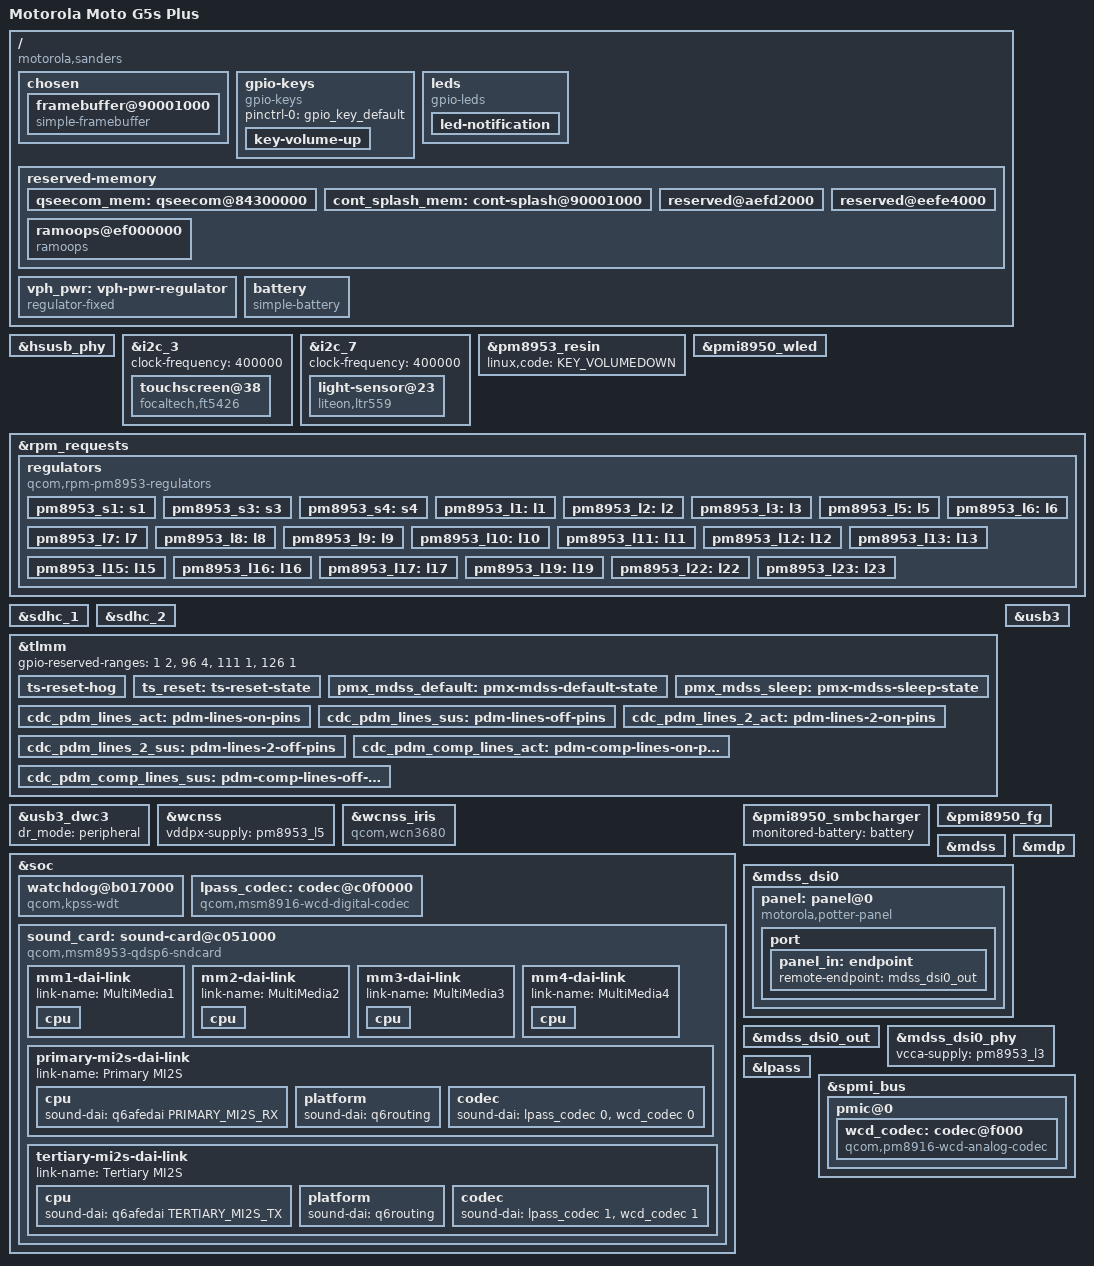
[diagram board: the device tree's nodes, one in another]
// SPDX-License-Identifier: BSD-3-Clause
/*
 * Motorola Moto G5s Plus (sanders) — proof-of-life DTS.
 * Derivado de msm8953-motorola-potter.dts (Moto G5 Plus). Hardware base
 * idêntico (msm8953 + pm8953 + pmi8950, display 1080x1920, MMC, USB, touch
 * Synaptics RMI4). Painel pode diferir (Tianma NT35596 ou DJN ILI7807D no
 * sanders); por enquanto reaproveitamos só o cont_splash_mem do bootloader.
 */
/dts-v1/;

#include "msm8953.dtsi"
#include "pm8953.dtsi"
#include "pmi8950.dtsi"

/delete-node/ &cont_splash_mem;
/delete-node/ &qseecom_mem;

/ {
	model = "Motorola Moto G5s Plus";
	compatible = "motorola,sanders", "qcom,msm8953";
	chassis-type = "handset";
	qcom,msm-id = <293 0>;
	/* Cobre todas as 6 variantes do sanders no fork lk2nd:
	 * p1, p2, p3-1, p3-2, p4-1, p4-2. lk2nd casa contra
	 * lk2nd_dt_override e seleciona automaticamente. */
	qcom,board-id = <0x4B 0x8100>,
			<0x4B 0x8200>,
			<0x4B 0x8300>,
			<0x4B 0x83B0>,
			<0x4B 0x8400>,
			<0x4C 0x8400>;

	chosen {
		#address-cells = <2>;
		#size-cells = <2>;
		ranges;

		framebuffer@90001000 {
			compatible = "simple-framebuffer";
			/* Era (2220 * 1920 * 3) = 12.787.200 bytes — quase o
			 * dobro do que cont_splash_mem reserva (1080*1920*3 =
			 * 6.220.800, no-map). simplefb.c faz
			 * ioremap_wc(smem_start, resource_size(mem)) usando o
			 * tamanho cheio do reg, nao width*height*stride — os
			 * ~6.5MB extras mapeados write-combining cairiam em
			 * RAM normal nao reservada, dual-mapped com atributos
			 * de cache incompativeis (risco real de corrupcao).
			 * 1080, nao 2220 — bate com stride (1080*3=3240) *
			 * height (1920) e com o cont_splash_mem real. */
			reg = <0 0x90001000 0 (1080 * 1920 * 3)>;

			width = <1080>;
			height = <1920>;
			stride = <(1080 * 3)>;
			format = "r8g8b8";

			power-domains = <&gcc MDSS_GDSC>;

			clocks = <&gcc GCC_MDSS_AHB_CLK>,
				 <&gcc GCC_MDSS_AXI_CLK>,
				 <&gcc GCC_MDSS_VSYNC_CLK>,
				 <&gcc GCC_MDSS_MDP_CLK>,
				 <&gcc GCC_MDSS_BYTE0_CLK>,
				 <&gcc GCC_MDSS_PCLK0_CLK>,
				 <&gcc GCC_MDSS_ESC0_CLK>;
		};
	};

	gpio-keys {
		compatible = "gpio-keys";

		pinctrl-names = "default";
		pinctrl-0 = <&gpio_key_default>;

		key-volume-up {
			label = "Volume Up";
			gpios = <&tlmm 85 GPIO_ACTIVE_LOW>;
			linux,code = <KEY_VOLUMEUP>;
		};
	};

	/*
	 * LED de notificacao frontal — branco unico, ligado no MPP2 do
	 * pmi8950 como current-sink. Downstream Moto (qpnp-leds) usava modo
	 * "manual" com source-sel=1 e current=5mA. No mainline atual nao ha
	 * driver MPP-as-current-sink; usamos leds-gpio (on/off apenas).
	 * Brilho/PWM via pmi8950_pwm fica como upgrade futuro.
	 */
	leds {
		compatible = "gpio-leds";

		led-notification {
			label = "white:notification";
			gpios = <&pmi8950_mpps 1 GPIO_ACTIVE_HIGH>;
			default-state = "off";
		};
	};

	reserved-memory {
		qseecom_mem: qseecom@84300000 {
			reg = <0x0 0x84300000 0x0 0x2000000>;
			no-map;
		};

		cont_splash_mem: cont-splash@90001000 {
			reg = <0x0 0x90001000 0x0 (1080 * 1920 * 3)>;
			no-map;
		};

		reserved@aefd2000 {
			reg = <0x0 0xaefd2000 0x0 0x2e000>;
			no-map;
		};

		reserved@eefe4000 {
			reg = <0x0 0xeefe4000 0x0 0x1c000>;
			no-map;
		};

		ramoops@ef000000 {
			compatible = "ramoops";
			reg = <0x0 0xef000000 0x0 0x80000>;
			console-size = <0x40000>;
			ftrace-size = <0>;
			record-size = <0x3f800>;
			pmsg-size = <0x800>;
		};
	};

	vph_pwr: vph-pwr-regulator {
		compatible = "regulator-fixed";
		regulator-name = "vph_pwr";
		regulator-always-on;
		regulator-boot-on;
	};

	/*
	 * Valores extraidos do DTB de fabrica real (decompilado de
	 * chroot_rootfs_motorola-potter/boot/msm8953-motorola-potter.dtb,
	 * mesma bateria do sanders/potter): charge-full-design 0x2e5b30 =
	 * 3038000 uAh, voltage-min 0x33e140 = 3400000 uV, voltage-max
	 * 0x432380 = 4400000 uV, constant-charge-current-max 0xf4240 =
	 * 1000000 uA. So a descricao da bateria; nao ha driver mainline
	 * pra charger/fuel-gauge deste PMIC ainda (ver &pmi8950_smbcharger
	 * e &pmi8950_fg abaixo) — os numeros ficam prontos pro dia que
	 * existir driver.
	 */
	battery: battery {
		compatible = "simple-battery";
		charge-full-design-microamp-hours = <3038000>;
		voltage-min-design-microvolt = <3400000>;
		voltage-max-design-microvolt = <4400000>;
		constant-charge-current-max-microamp = <1000000>;
	};
};



&hsusb_phy {
	vdd-supply = <&pm8953_l3>;
	vdda-pll-supply = <&pm8953_l7>;
	vdda-phy-dpdm-supply = <&pm8953_l13>;

	status = "okay";
};

&i2c_3 {
	status = "okay";
	clock-frequency = <400000>;	/* stock Android usa 400kHz no FT5436 */

	/* Forca PIO (sem DMA) — o controller mainline pode estar com
	 * bug DMA em transactions especificas do FT5436. */
	/delete-property/ dmas;
	/delete-property/ dma-names;

	/* Moto G5s Plus stock Android usa Focaltech FT5436 @ 0x38 com
	 * VDD em pm8953_l10 (2.85V, always-on) e VCC_I2C em pm8953_l5
	 * (1.8V). Reset GPIO 64, IRQ GPIO 65. (Nao Synaptics RMI4 como
	 * o irmao potter.) */
	touchscreen@38 {
		reg = <0x38>;
		compatible = "focaltech,ft5426";

		interrupt-parent = <&tlmm>;
		interrupts = <65 IRQ_TYPE_EDGE_FALLING>;

		/* Reset GPIO controlado via gpio-hog (sempre HIGH) — o pulse
		 * curto do driver (~5ms) estava deixando o chip num estado
		 * de boot e o regmap_bulk_read dava -ETIMEDOUT. */

		vcc-supply = <&pm8953_l10>;
		iovcc-supply = <&pm8953_l5>;

		touchscreen-size-x = <1080>;
		touchscreen-size-y = <1920>;
	};
};

/*
 * Sensor de proximidade + luz ambiente: LiteON LTR559 no i2c_7 @ 0x23.
 *
 * Stock Android (msm8953-sanders.dtsi):
 *   liteon@23 {
 *     compatible = "liteon,ltr559";
 *     vdd-supply = <&pm8953_l10>;       // 2.85V (mesmo do FT5436)
 *     vio-supply = <&pm8953_l6>;        // 1.8V always-on
 *     interrupts = <86 IRQ_TYPE_EDGE_FALLING>;
 *     ltr,ps-threshold = <800>;         // params calibrados pela Moto;
 *     ltr,ps-nearoffset = <20>;         // mainline ltr501 driver usa
 *     ltr,ps-faroffset = <15>;          // proximity-near-level (75).
 *   }
 *
 * Driver mainline: drivers/iio/light/ltr501.c (cobre ltr501/559/301).
 * Expoe via IIO: in_illuminance_raw, in_proximity_raw, eventos em
 * /dev/iio:device*. Phosh/iio-sensor-proxy consomem direto.
 *
 * Acel/giro/magnetom NAO estao em I2C — passam pela SSC (Sensor
 * Subsystem) no SLPI/DSP, caminho proprietario sem driver mainline
 * pratico hoje.
 */
&i2c_7 {
	status = "okay";
	clock-frequency = <400000>;

	light-sensor@23 {
		compatible = "liteon,ltr559";
		reg = <0x23>;

		vdd-supply = <&pm8953_l10>;
		vddio-supply = <&pm8953_l6>;

		interrupt-parent = <&tlmm>;
		interrupts = <86 IRQ_TYPE_EDGE_FALLING>;

		proximity-near-level = <75>;
	};
};

&pm8953_resin {
	linux,code = <KEY_VOLUMEDOWN>;
	status = "okay";
};

&pmi8950_wled {
	qcom,current-limit-microamp = <25000>;
	qcom,num-strings = <3>;
	qcom,external-pfet;
	qcom,cabc;

	status = "okay";
};

&rpm_requests {
	regulators {
		compatible = "qcom,rpm-pm8953-regulators";
		vdd_s1-supply = <&vph_pwr>;
		vdd_s2-supply = <&vph_pwr>;
		vdd_s3-supply = <&vph_pwr>;
		vdd_s4-supply = <&vph_pwr>;
		vdd_s5-supply = <&vph_pwr>;
		vdd_s6-supply = <&vph_pwr>;
		vdd_s7-supply = <&vph_pwr>;
		vdd_l1-supply = <&pm8953_s3>;
		vdd_l2_l3-supply = <&pm8953_s3>;
		vdd_l4_l5_l6_l7_l16_l19-supply = <&pm8953_s4>;
		vdd_l8_l11_l12_l13_l14_l15-supply = <&vph_pwr>;
		vdd_l9_l10_l17_l18_l22-supply = <&vph_pwr>;

		pm8953_s1: s1 {
			regulator-min-microvolt = <863000>;
			regulator-max-microvolt = <1152000>;
		};

		pm8953_s3: s3 {
			regulator-min-microvolt = <1224000>;
			regulator-max-microvolt = <1224000>;
		};

		pm8953_s4: s4 {
			regulator-min-microvolt = <1896000>;
			regulator-max-microvolt = <2048000>;
		};

		pm8953_l1: l1 {
			regulator-min-microvolt = <1000000>;
			regulator-max-microvolt = <1100000>;
		};

		pm8953_l2: l2 {
			regulator-min-microvolt = <1000000>;
			regulator-max-microvolt = <1000000>;
		};

		pm8953_l3: l3 {
			regulator-min-microvolt = <925000>;
			regulator-max-microvolt = <925000>;
			regulator-allow-set-load;
		};

		pm8953_l5: l5 {
			regulator-min-microvolt = <1800000>;
			regulator-max-microvolt = <1800000>;
		};

		pm8953_l6: l6 {
			regulator-min-microvolt = <1800000>;
			regulator-max-microvolt = <1800000>;
			regulator-always-on;
		};

		pm8953_l7: l7 {
			regulator-min-microvolt = <1800000>;
			regulator-max-microvolt = <1900000>;
		};

		pm8953_l8: l8 {
			regulator-min-microvolt = <2900000>;
			regulator-max-microvolt = <2900000>;
		};

		pm8953_l9: l9 {
			regulator-min-microvolt = <3000000>;
			regulator-max-microvolt = <3300000>;
		};

		pm8953_l10: l10 {
			/* Touchscreen FT5436 VDD (2.85V). Stock Android tem
			 * always-on para manter o chip alimentado sempre. */
			regulator-min-microvolt = <2850000>;
			regulator-max-microvolt = <2850000>;
			regulator-always-on;
		};

		pm8953_l11: l11 {
			regulator-min-microvolt = <2800000>;
			regulator-max-microvolt = <3000000>;
		};

		pm8953_l12: l12 {
			regulator-min-microvolt = <1800000>;
			regulator-max-microvolt = <3000000>;
		};

		pm8953_l13: l13 {
			regulator-min-microvolt = <3075000>;
			regulator-max-microvolt = <3125000>;
		};

		pm8953_l15: l15 {
			regulator-min-microvolt = <1800000>;
			regulator-max-microvolt = <1800000>;
		};

		pm8953_l16: l16 {
			regulator-min-microvolt = <1800000>;
			regulator-max-microvolt = <1800000>;
		};

		pm8953_l17: l17 {
			regulator-min-microvolt = <2800000>;
			regulator-max-microvolt = <3000000>;
		};

		pm8953_l19: l19 {
			regulator-min-microvolt = <1200000>;
			regulator-max-microvolt = <1350000>;
		};

		pm8953_l22: l22 {
			regulator-always-on;
			regulator-min-microvolt = <2800000>;
			regulator-max-microvolt = <2850000>;
		};

		pm8953_l23: l23 {
			regulator-min-microvolt = <975000>;
			regulator-max-microvolt = <1225000>;
		};
	};
};

&sdhc_1 {
	vmmc-supply = <&pm8953_l8>;
	vqmmc-supply = <&pm8953_l5>;

	status = "okay";
};

&sdhc_2 {
	vmmc-supply = <&pm8953_l11>;
	vqmmc-supply = <&pm8953_l12>;

	cd-gpios = <&tlmm 133 GPIO_ACTIVE_LOW>;

	pinctrl-names = "default", "sleep";
	pinctrl-0 = <&sdc2_clk_on &sdc2_cmd_on &sdc2_data_on &sdc2_cd_off>;
	pinctrl-1 = <&sdc2_clk_off &sdc2_cmd_off &sdc2_data_off &sdc2_cd_off>;

	status = "okay";
};

&tlmm {
	gpio-reserved-ranges = <1 2>, <96 4>, <111 1>, <126 1>;

	/* Mantem o touchscreen FT5436 sempre fora de reset. */
	ts-reset-hog {
		gpio-hog;
		gpios = <64 GPIO_ACTIVE_HIGH>;
		output-high;
		line-name = "touchscreen-reset";
	};

	ts_reset: ts-reset-state {
		pins = "gpio64";
		function = "gpio";
		drive-strength = <2>;
		bias-pull-up;
		output-high;
	};

	pmx_mdss_default: pmx-mdss-default-state {
		pins = "gpio61";
		function = "gpio";
		drive-strength = <8>;
		bias-disable;
		output-high;
	};

	pmx_mdss_sleep: pmx-mdss-sleep-state {
		pins = "gpio61";
		function = "gpio";
		drive-strength = <2>;
		bias-pull-down;
	};

	cdc_pdm_lines_act: pdm-lines-on-pins {
		pins = "gpio69", "gpio73", "gpio74";
		function = "cdc_pdm0";
		drive-strength = <8>;
	};

	cdc_pdm_lines_sus: pdm-lines-off-pins {
		pins = "gpio69", "gpio73", "gpio74";
		function = "cdc_pdm0";
		drive-strength = <2>;
		bias-disable;
	};

	cdc_pdm_lines_2_act: pdm-lines-2-on-pins {
		pins = "gpio70", "gpio71", "gpio72";
		function = "cdc_pdm0";
		drive-strength = <8>;
	};

	cdc_pdm_lines_2_sus: pdm-lines-2-off-pins {
		pins = "gpio70", "gpio71", "gpio72";
		function = "cdc_pdm0";
		drive-strength = <2>;
		bias-disable;
	};

	cdc_pdm_comp_lines_act: pdm-comp-lines-on-pins {
		pins = "gpio67", "gpio68";
		function = "cdc_pdm0";
		drive-strength = <8>;
	};

	cdc_pdm_comp_lines_sus: pdm-comp-lines-off-pins {
		pins = "gpio67", "gpio68";
		function = "cdc_pdm0";
		drive-strength = <2>;
		bias-disable;
	};
};

&usb3 {
	status = "okay";
};

&usb3_dwc3 {
	/delete-property/ usb-role-switch;
	dr_mode = "peripheral";
};

/*
 * Wi-Fi/Bluetooth (WCN3680B "pronto" + iris RF transceiver).
 *
 * Reguladores extraidos do DTB stock Android (qcom,wcnss-wlan):
 *   - vddxo  -> pm8953_l7  (1.8V)
 *   - vddrfa -> pm8953_l19 (1.2V)
 *   - vddpa  -> pm8953_l9  (3.0V)
 *   - vdddig -> pm8953_l5  (1.8V)
 *   - vddpx  -> pm8953_l5  (1.8V)
 *   - vddcx/vddmx ja vem via power-domains do msm8953.dtsi
 *
 * Firmware necessario em /lib/firmware/wlan/prima/ (extraido do
 * Android stock NON-HLOS.bin).
 */
&wcnss {
	vddpx-supply = <&pm8953_l5>;

	status = "okay";
};

&wcnss_iris {
	compatible = "qcom,wcn3680";

	vddxo-supply = <&pm8953_l7>;
	vddrfa-supply = <&pm8953_l19>;
	vddpa-supply = <&pm8953_l9>;
	vdddig-supply = <&pm8953_l5>;
};

/*
 * NAO existe TI bq27426 neste hardware. O DTB de fabrica real
 * (chroot_rootfs_motorola-potter/boot/msm8953-motorola-potter.dtb)
 * nao menciona bq27426 em lugar nenhum; o fuel-gauge de fabrica e o
 * integrado no proprio PMI8996 (ver &pmi8950_fg abaixo). Um no
 * "ti,bq27426" chegou a existir aqui, dentro de &soc — alem de nao
 * ter respaldo em hardware, "ti,bq27426" so casa via I2C
 * (bq27xxx_battery_i2c_of_match_table) e &soc e barramento de
 * periferico mapeado em memoria, entao nunca bindaria de qualquer
 * forma. Removido em 2026-09-02.
 */
&soc {
	watchdog@b017000 {
		compatible = "qcom,kpss-wdt";
		reg = <0x0b017000 0x1000>;
		clocks = <&sleep_clk>;
		status = "okay";
	};
};

/*
 * Charger + fuel-gauge integrados no PMI8996 (confirmados no DTB de
 * fabrica: smbchager@1000 / fuel-gauge@4000 dentro do pmic@2 do
 * PMI8950). Habilitados aqui, mas SEM efeito pratico ainda: nao
 * existe driver mainline pra "qcom,pmi8996-smbchg" nem
 * "qcom,pmi8996-fg" (verificado em drivers/power/supply/ e
 * Documentation/devicetree/bindings/power/supply/ — nenhum dos dois
 * compatible aparece). Os nos ficam prontos, documentados e corretos,
 * pro dia que alguem escrever/portar o driver — ate la sao inertes
 * (mesmo resultado pratico que /sys/class/power_supply/ vazio, hoje
 * confirmado ao vivo). Labels adicionados em
 * kernel/0004-pmi8950-battery-charger-nodes.patch (pmi8950.dtsi
 * upstream nao tem esses nos).
 */
&pmi8950_smbcharger {
	monitored-battery = <&battery>;
	status = "okay";
};

&pmi8950_fg {
	monitored-battery = <&battery>;
	power-supplies = <&pmi8950_smbcharger>;
	status = "okay";
};

/*
 * Painel MIPI-DSI nativo (Moto G5 Plus / potter / sanders)
 *
 * O lk2nd detecta o painel de fabrica no boot e atualiza dinamicamente
 * o compatible "motorola,potter-panel" para "tianma,tl052vdxp02" ou
 * "boe,bs052fhm-a00-6c01" dependendo do hardware fisico instalado.
 */
&mdss {
	status = "okay";
};

&mdp {
	status = "okay";
};

&mdss_dsi0 {
	vdda-supply = <&pm8953_s3>;
	vddio-supply = <&pm8953_l6>;

	status = "okay";

	panel: panel@0 {
		compatible = "motorola,potter-panel", "tianma,tl052vdxp02";
		reg = <0>;

		backlight = <&pmi8950_wled>;

		pinctrl-names = "default", "sleep";
		pinctrl-0 = <&pmx_mdss_default>;
		pinctrl-1 = <&pmx_mdss_sleep>;

		reset-gpios = <&tlmm 61 GPIO_ACTIVE_LOW>;

		vsp-supply = <&lab>;
		vsn-supply = <&ibb>;

		port {
			panel_in: endpoint {
				remote-endpoint = <&mdss_dsi0_out>;
			};
		};
	};
};

&mdss_dsi0_out {
	data-lanes = <0 1 2 3>;
	remote-endpoint = <&panel_in>;
};

&mdss_dsi0_phy {
	vcca-supply = <&pm8953_l3>;
	status = "okay";
};

/*
 * Subsistema de Audio Qualcomm (Hexagon ADSP PIL + QDSP6 + Codecs PM8953)
 */
&lpass {
	status = "okay";
};

&spmi_bus {
	/*
	 * codec@f000 estava sob pmic@1 (seguindo referencia de boards
	 * msm8916/pm8916, onde o codec analogico vive na 2a USID do PMIC).
	 * No potter/sanders (pm8953), a USID 1 nao tem driver bindado em
	 * /sys/bus/spmi/devices/0-01 (sem erro no dmesg, sem deferred-probe
	 * — silenciosamente sem probe, sugerindo falha de leitura SPMI /
	 * nao ha chip fisico respondendo nessa USID). pmic@0 (USID 0, onde
	 * adc/gpio/pon/rtc/temp-alarm ja probam OK) tem 0xf000 livre —
	 * tentativa de mover o codec pra la. Confirmar contra o DTB de
	 * fabrica antes de assumir que isso e definitivo.
	 */
	pmic@0 {
		wcd_codec: codec@f000 {
			compatible = "qcom,pm8916-wcd-analog-codec";
			reg = <0xf000 0x200>;
			reg-names = "pmic-codec-core";
			clocks = <&q6afecc LPASS_CLK_ID_INTERNAL_DIGITAL_CODEC_CORE
					   LPASS_CLK_ATTRIBUTE_COUPLE_NO>;
			clock-names = "mclk";
			interrupt-parent = <&spmi_bus>;
			interrupts = <0x1 0xf0 0x0 IRQ_TYPE_NONE>,
				     <0x1 0xf0 0x1 IRQ_TYPE_NONE>,
				     <0x1 0xf0 0x2 IRQ_TYPE_NONE>,
				     <0x1 0xf0 0x3 IRQ_TYPE_NONE>,
				     <0x1 0xf0 0x4 IRQ_TYPE_NONE>,
				     <0x1 0xf0 0x5 IRQ_TYPE_NONE>,
				     <0x1 0xf0 0x6 IRQ_TYPE_NONE>,
				     <0x1 0xf0 0x7 IRQ_TYPE_NONE>,
				     <0x1 0xf1 0x0 IRQ_TYPE_NONE>,
				     <0x1 0xf1 0x1 IRQ_TYPE_NONE>,
				     <0x1 0xf1 0x2 IRQ_TYPE_NONE>,
				     <0x1 0xf1 0x3 IRQ_TYPE_NONE>,
				     <0x1 0xf1 0x4 IRQ_TYPE_NONE>,
				     <0x1 0xf1 0x5 IRQ_TYPE_NONE>;
			interrupt-names = "cdc_spk_cnp_int",
					  "cdc_spk_clip_int",
					  "cdc_spk_ocp_int",
					  "mbhc_ins_rem_det1",
					  "mbhc_but_rel_det",
					  "mbhc_but_press_det",
					  "mbhc_ins_rem_det",
					  "mbhc_switch_int",
					  "cdc_ear_ocp_int",
					  "cdc_hphr_ocp_int",
					  "cdc_hphl_ocp_int",
					  "cdc_ear_cnp_int",
					  "cdc_hphr_cnp_int",
					  "cdc_hphl_cnp_int";
			#sound-dai-cells = <1>;

			status = "okay";

			qcom,micbias1-ext-cap;
			qcom,micbias2-ext-cap;
			qcom,hphl-jack-type-normally-open;
			qcom,mbhc-vthreshold-low = <75 150 237 450 500>;
			qcom,mbhc-vthreshold-high = <75 150 237 450 500>;

			vdd-cdc-io-supply = <&pm8953_l5>;
			vdd-cdc-tx-rx-cx-supply = <&pm8953_s4>;
			vdd-micbias-supply = <&pm8953_l13>;
		};
	};
};

&soc {
	lpass_codec: codec@c0f0000 {
		compatible = "qcom,msm8916-wcd-digital-codec";
		reg = <0x0c0f0000 0x400>;
		#sound-dai-cells = <1>;

		clocks = <&q6afecc LPASS_CLK_ID_INTERNAL_DIGITAL_CODEC_CORE
				   LPASS_CLK_ATTRIBUTE_COUPLE_NO>,
			 <&xo_board>;
		clock-names = "mclk", "ahbix-clk";
		status = "okay";
	};

	sound_card: sound-card@c051000 {
		compatible = "qcom,msm8953-qdsp6-sndcard";
		reg = <0x0c051000 0x4>,
		      <0x0c051004 0x4>,
		      <0x0c055000 0x4>,
		      <0x0c052000 0x4>;
		reg-names = "mic-iomux",
			    "spkr-iomux",
			    "pri-iomux",
			    "quin-iomux";

		model = "motorola-potter";

		pinctrl-names = "default", "sleep";
		pinctrl-0 = <&cdc_pdm_lines_act &cdc_pdm_lines_2_act &cdc_pdm_comp_lines_act>;
		pinctrl-1 = <&cdc_pdm_lines_sus &cdc_pdm_lines_2_sus &cdc_pdm_comp_lines_act>;

		audio-routing =
			"AMIC1", "MIC BIAS External1",
			"AMIC2", "MIC BIAS External2",
			"AMIC3", "MIC BIAS External1",
			"MM_DL1", "MultiMedia1 Playback",
			"MM_DL3", "MultiMedia3 Playback",
			"MM_DL4", "MultiMedia4 Playback",
			"MultiMedia2 Capture", "MM_UL2";

		status = "okay";

		mm1-dai-link {
			link-name = "MultiMedia1";
			cpu {
				sound-dai = <&q6asmdai MSM_FRONTEND_DAI_MULTIMEDIA1>;
			};
		};

		mm2-dai-link {
			link-name = "MultiMedia2";
			cpu {
				sound-dai = <&q6asmdai MSM_FRONTEND_DAI_MULTIMEDIA2>;
			};
		};

		mm3-dai-link {
			link-name = "MultiMedia3";
			cpu {
				sound-dai = <&q6asmdai MSM_FRONTEND_DAI_MULTIMEDIA3>;
			};
		};

		mm4-dai-link {
			link-name = "MultiMedia4";
			cpu {
				sound-dai = <&q6asmdai MSM_FRONTEND_DAI_MULTIMEDIA4>;
			};
		};

		primary-mi2s-dai-link {
			link-name = "Primary MI2S";
			cpu {
				sound-dai = <&q6afedai PRIMARY_MI2S_RX>;
			};

			platform {
				sound-dai = <&q6routing>;
			};

			codec {
				sound-dai = <&lpass_codec 0>, <&wcd_codec 0>;
			};
		};

		tertiary-mi2s-dai-link {
			link-name = "Tertiary MI2S";
			cpu {
				sound-dai = <&q6afedai TERTIARY_MI2S_TX>;
			};

			platform {
				sound-dai = <&q6routing>;
			};

			codec {
				sound-dai = <&lpass_codec 1>, <&wcd_codec 1>;
			};
		};
	};
};



